# STM32H7x7_CM4 register map
File version: 1.0
CPU: CM4 r0p1, little endian, MPU, FPU, 4 interrupt priority bits
Registers are 32-bit, read-write, reset 0x0 unless marked. A register's access mark holds for its fields unless they carry their own. Offsets are from the block's base; [hi:lo] are bit positions; {n}, {i} and the like mark numbered series; 'fields as' and 'values as' point back to an identical list.

## SAI4 — SAI
Base 0x58005400
Same registers: SAI1 0x40015800, SAI2 0x40015C00, SAI3 0x40016000
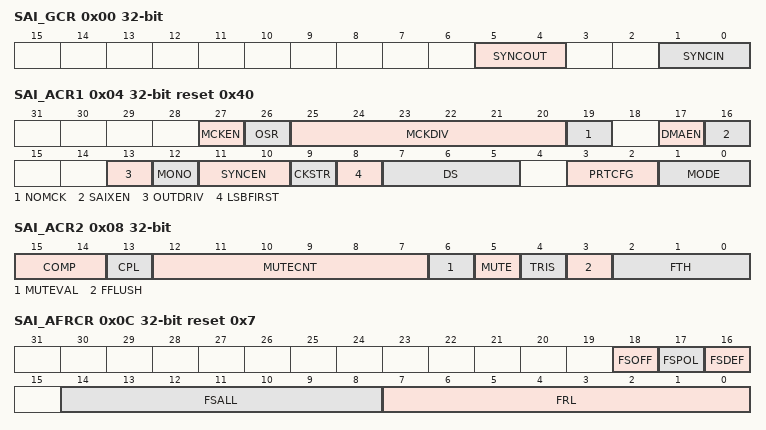
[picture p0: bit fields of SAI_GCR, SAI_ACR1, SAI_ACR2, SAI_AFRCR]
0x00 SAI_GCR — Global configuration register
  [5:4] SYNCOUT — Synchronization outputs These bits are set and cleared by software.
  [1:0] SYNCIN — Synchronization inputs
0x04 SAI_ACR1 reset 0x40 — Configuration register 1
  [27] MCKEN — Master clock generation enable
  [26] OSR — Oversampling ratio for master clock
  [25:20] MCKDIV — Master clock divider. These bits are set and cleared by software. These bits are meaningless when the audio block operates in slave mode. They have to be configured when the audio block is disabled. Others: the master clock frequency is calculated accordingly to the following formula:
  [19] NOMCK — No divider
  [17] DMAEN — DMA enable. This bit is set and cleared by software. Note: Since the audio block defaults to operate as a transmitter after reset, the MODE[1:0] bits must be configured before setting DMAEN to avoid a DMA request in receiver mode.
  [16] SAIXEN — Audio block enable where x is A or B. This bit is set by software. To switch off the audio block, the application software must program this bit to 0 and poll the bit till it reads back 0, meaning that the block is completely disabled. Before setting this bit to 1, check that it is set to 0, otherwise the enable command will not be taken into account. This bit allows to control the state of SAIx audio block. If it is disabled when an audio frame transfer is ongoing, the ongoing transfer completes and the cell is fully disabled at the end of this audio frame transfer. Note: When SAIx block is configured in master mode, the clock must be present on the input of SAIx before setting SAIXEN bit.
  [13] OUTDRIV — Output drive. This bit is set and cleared by software. Note: This bit has to be set before enabling the audio block and after the audio block configuration.
  [12] MONO — Mono mode. This bit is set and cleared by software. It is meaningful only when the number of slots is equal to 2. When the mono mode is selected, slot 0 data are duplicated on slot 1 when the audio block operates as a transmitter. In reception mode, the slot1 is discarded and only the data received from slot 0 are stored. Refer to Section: Mono/stereo mode for more details.
  [11:10] SYNCEN — Synchronization enable. These bits are set and cleared by software. They must be configured when the audio sub-block is disabled. Note: The audio sub-block should be configured as asynchronous when SPDIF mode is enabled.
  [9] CKSTR — Clock strobing edge. This bit is set and cleared by software. It must be configured when the audio block is disabled. This bit has no meaning in SPDIF audio protocol.
  [8] LSBFIRST — Least significant bit first. This bit is set and cleared by software. It must be configured when the audio block is disabled. This bit has no meaning in AC97 audio protocol since AC97 data are always transferred with the MSB first. This bit has no meaning in SPDIF audio protocol since in SPDIF data are always transferred with LSB first.
  [7:5] DS — Data size. These bits are set and cleared by software. These bits are ignored when the SPDIF protocols are selected (bit PRTCFG[1:0]), because the frame and the data size are fixed in such case. When the companding mode is selected through COMP[1:0] bits, DS[1:0] are ignored since the data size is fixed to 8 bits by the algorithm. These bits must be configured when the audio block is disabled.
  [3:2] PRTCFG — Protocol configuration. These bits are set and cleared by software. These bits have to be configured when the audio block is disabled.
  [1:0] MODE — SAIx audio block mode immediately
0x08 SAI_ACR2 access per field — Configuration register 2
  [15:14] COMP rw — Companding mode. These bits are set and cleared by software. The -Law and the A-Law log are a part of the CCITT G.711 recommendation, the type of complement that will be used depends on CPL bit. The data expansion or data compression are determined by the state of bit MODE[0]. The data compression is applied if the audio block is configured as a transmitter. The data expansion is automatically applied when the audio block is configured as a receiver. Refer to Section: Companding mode for more details. Note: Companding mode is applicable only when TDM is selected.
  [13] CPL rw — Complement bit. This bit is set and cleared by software. It defines the type of complement to be used for companding mode Note: This bit has effect only when the companding mode is -Law algorithm or A-Law algorithm.
  [12:7] MUTECNT rw — Mute counter. These bits are set and cleared by software. They are used only in reception mode. The value set in these bits is compared to the number of consecutive mute frames detected in reception. When the number of mute frames is equal to this value, the flag MUTEDET will be set and an interrupt will be generated if bit MUTEDETIE is set. Refer to Section: Mute mode for more details.
  [6] MUTEVAL rw — Mute value. This bit is set and cleared by software.It must be written before enabling the audio block: SAIXEN. This bit is meaningful only when the audio block operates as a transmitter, the number of slots is lower or equal to 2 and the MUTE bit is set. If more slots are declared, the bit value sent during the transmission in mute mode is equal to 0, whatever the value of MUTEVAL. if the number of slot is lower or equal to 2 and MUTEVAL = 1, the MUTE value transmitted for each slot is the one sent during the previous frame. Refer to Section: Mute mode for more details. Note: This bit is meaningless and should not be used for SPDIF audio blocks.
  [5] MUTE rw — Mute. This bit is set and cleared by software. It is meaningful only when the audio block operates as a transmitter. The MUTE value is linked to value of MUTEVAL if the number of slots is lower or equal to 2, or equal to 0 if it is greater than 2. Refer to Section: Mute mode for more details. Note: This bit is meaningless and should not be used for SPDIF audio blocks.
  [4] TRIS rw — Tristate management on data line. This bit is set and cleared by software. It is meaningful only if the audio block is configured as a transmitter. This bit is not used when the audio block is configured in SPDIF mode. It should be configured when SAI is disabled. Refer to Section: Output data line management on an inactive slot for more details.
  [3] FFLUSH wo — FIFO flush. This bit is set by software. It is always read as 0. This bit should be configured when the SAI is disabled.
  [2:0] FTH rw — FIFO threshold. This bit is set and cleared by software.
0x0C SAI_AFRCR access per field reset 0x7 — This register has no meaning in AC97 and SPDIF audio protocol
  [18] FSOFF rw — Frame synchronization offset. This bit is set and cleared by software. It is meaningless and is not used in AC97 or SPDIF audio block configuration. This bit must be configured when the audio block is disabled.
  [17] FSPOL rw — Frame synchronization polarity. This bit is set and cleared by software. It is used to configure the level of the start of frame on the FS signal. It is meaningless and is not used in AC97 or SPDIF audio block configuration. This bit must be configured when the audio block is disabled.
  [16] FSDEF ro — Frame synchronization definition. This bit is set and cleared by software. When the bit is set, the number of slots defined in the SAI_xSLOTR register has to be even. It means that half of this number of slots will be dedicated to the left channel and the other slots for the right channel (e.g: this bit has to be set for I2S or MSB/LSB-justified protocols...). This bit is meaningless and is not used in AC97 or SPDIF audio block configuration. It must be configured when the audio block is disabled.
  [14:8] FSALL rw — Frame synchronization active level length. These bits are set and cleared by software. They specify the length in number of bit clock (SCK) + 1 (FSALL[6:0] + 1) of the active level of the FS signal in the audio frame These bits are meaningless and are not used in AC97 or SPDIF audio block configuration. They must be configured when the audio block is disabled.
  [7:0] FRL rw — Frame length. These bits are set and cleared by software. They define the audio frame length expressed in number of SCK clock cycles: the number of bits in the frame is equal to FRL[7:0] + 1. The minimum number of bits to transfer in an audio frame must be equal to 8, otherwise the audio block will behaves in an unexpected way. This is the case when the data size is 8 bits and only one slot 0 is defined in NBSLOT[4:0] of SAI_xSLOTR register (NBSLOT[3:0] = 0000). In master mode, if the master clock (available on MCLK_x pin) is used, the frame length should be aligned with a number equal to a power of 2, ranging from 8 to 256. When the master clock is not used (NODIV = 1), it is recommended to program the frame length to an value ranging from 8 to 256. These bits are meaningless and are not used in AC97 or SPDIF audio block configuration.
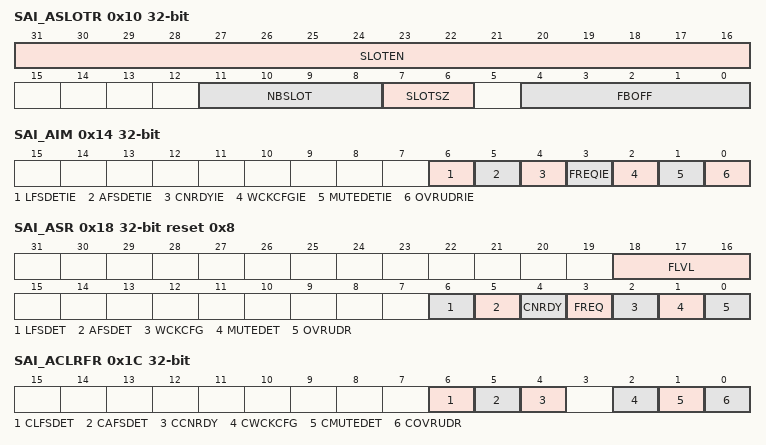
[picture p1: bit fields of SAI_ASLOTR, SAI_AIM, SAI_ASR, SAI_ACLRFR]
0x10 SAI_ASLOTR — This register has no meaning in AC97 and SPDIF audio protocol
  [31:16] SLOTEN — Slot enable. These bits are set and cleared by software. Each SLOTEN bit corresponds to a slot position from 0 to 15 (maximum 16 slots). The slot must be enabled when the audio block is disabled. They are ignored in AC97 or SPDIF mode.
  [11:8] NBSLOT — Number of slots in an audio frame. These bits are set and cleared by software. The value set in this bitfield represents the number of slots + 1 in the audio frame (including the number of inactive slots). The maximum number of slots is 16. The number of slots should be even if FSDEF bit in the SAI_xFRCR register is set. The number of slots must be configured when the audio block is disabled. They are ignored in AC97 or SPDIF mode.
  [7:6] SLOTSZ — Slot size This bits is set and cleared by software. The slot size must be higher or equal to the data size. If this condition is not respected, the behavior of the SAI will be undetermined. Refer to Section: Output data line management on an inactive slot for information on how to drive SD line. These bits must be set when the audio block is disabled. They are ignored in AC97 or SPDIF mode.
  [4:0] FBOFF — First bit offset These bits are set and cleared by software. The value set in this bitfield defines the position of the first data transfer bit in the slot. It represents an offset value. In transmission mode, the bits outside the data field are forced to 0. In reception mode, the extra received bits are discarded. These bits must be set when the audio block is disabled. They are ignored in AC97 or SPDIF mode.
0x14 SAI_AIM — Interrupt mask register 2
  [6] LFSDETIE — Late frame synchronization detection interrupt enable. This bit is set and cleared by software. When this bit is set, an interrupt will be generated if the LFSDET bit is set in the SAI_xSR register. This bit is meaningless in AC97, SPDIF mode or when the audio block operates as a master.
  [5] AFSDETIE — Anticipated frame synchronization detection interrupt enable. This bit is set and cleared by software. When this bit is set, an interrupt will be generated if the AFSDET bit in the SAI_xSR register is set. This bit is meaningless in AC97, SPDIF mode or when the audio block operates as a master.
  [4] CNRDYIE — Codec not ready interrupt enable (AC97). This bit is set and cleared by software. When the interrupt is enabled, the audio block detects in the slot 0 (tag0) of the AC97 frame if the Codec connected to this line is ready or not. If it is not ready, the CNRDY flag in the SAI_xSR register is set and an interruption i generated. This bit has a meaning only if the AC97 mode is selected through PRTCFG[1:0] bits and the audio block is operates as a receiver.
  [3] FREQIE — FIFO request interrupt enable. This bit is set and cleared by software. When this bit is set, an interrupt is generated if the FREQ bit in the SAI_xSR register is set. Since the audio block defaults to operate as a transmitter after reset, the MODE bit must be configured before setting FREQIE to avoid a parasitic interruption in receiver mode,
  [2] WCKCFGIE — Wrong clock configuration interrupt enable. This bit is set and cleared by software. This bit is taken into account only if the audio block is configured as a master (MODE[1] = 0) and NODIV = 0. It generates an interrupt if the WCKCFG flag in the SAI_xSR register is set. Note: This bit is used only in TDM mode and is meaningless in other modes.
  [1] MUTEDETIE — Mute detection interrupt enable. This bit is set and cleared by software. When this bit is set, an interrupt is generated if the MUTEDET bit in the SAI_xSR register is set. This bit has a meaning only if the audio block is configured in receiver mode.
  [0] OVRUDRIE — Overrun/underrun interrupt enable. This bit is set and cleared by software. When this bit is set, an interrupt is generated if the OVRUDR bit in the SAI_xSR register is set.
0x18 SAI_ASR ro reset 0x8 — Status register
  [18:16] FLVL — FIFO level threshold. This bit is read only. The FIFO level threshold flag is managed only by hardware and its setting depends on SAI block configuration (transmitter or receiver mode). If the SAI block is configured as transmitter: If SAI block is configured as receiver:
  [6] LFSDET — Late frame synchronization detection. This bit is read only. This flag can be set only if the audio block is configured in slave mode. It is not used in AC97 or SPDIF mode. It can generate an interrupt if LFSDETIE bit is set in the SAI_xIM register. This flag is cleared when the software sets bit CLFSDET in SAI_xCLRFR register
  [5] AFSDET — Anticipated frame synchronization detection. This bit is read only. This flag can be set only if the audio block is configured in slave mode. It is not used in AC97or SPDIF mode. It can generate an interrupt if AFSDETIE bit is set in SAI_xIM register. This flag is cleared when the software sets CAFSDET bit in SAI_xCLRFR register.
  [4] CNRDY — Codec not ready. This bit is read only. This bit is used only when the AC97 audio protocol is selected in the SAI_xCR1 register and configured in receiver mode. It can generate an interrupt if CNRDYIE bit is set in SAI_xIM register. This flag is cleared when the software sets CCNRDY bit in SAI_xCLRFR register.
  [3] FREQ — FIFO request. This bit is read only. The request depends on the audio block configuration: If the block is configured in transmission mode, the FIFO request is related to a write request operation in the SAI_xDR. If the block configured in reception, the FIFO request related to a read request operation from the SAI_xDR. This flag can generate an interrupt if FREQIE bit is set in SAI_xIM register.
  [2] WCKCFG — Wrong clock configuration flag. This bit is read only. This bit is used only when the audio block operates in master mode (MODE[1] = 0) and NODIV = 0. It can generate an interrupt if WCKCFGIE bit is set in SAI_xIM register. This flag is cleared when the software sets CWCKCFG bit in SAI_xCLRFR register.
  [1] MUTEDET — Mute detection. This bit is read only. This flag is set if consecutive 0 values are received in each slot of a given audio frame and for a consecutive number of audio frames (set in the MUTECNT bit in the SAI_xCR2 register). It can generate an interrupt if MUTEDETIE bit is set in SAI_xIM register. This flag is cleared when the software sets bit CMUTEDET in the SAI_xCLRFR register.
  [0] OVRUDR — Overrun / underrun. This bit is read only. The overrun and underrun conditions can occur only when the audio block is configured as a receiver and a transmitter, respectively. It can generate an interrupt if OVRUDRIE bit is set in SAI_xIM register. This flag is cleared when the software sets COVRUDR bit in SAI_xCLRFR register.
0x1C SAI_ACLRFR wo — Clear flag register
  [6] CLFSDET — Clear late frame synchronization detection flag. This bit is write only. Programming this bit to 1 clears the LFSDET flag in the SAI_xSR register. This bit is not used in AC97or SPDIF mode Reading this bit always returns the value 0.
  [5] CAFSDET — Clear anticipated frame synchronization detection flag. This bit is write only. Programming this bit to 1 clears the AFSDET flag in the SAI_xSR register. It is not used in AC97or SPDIF mode. Reading this bit always returns the value 0.
  [4] CCNRDY — Clear Codec not ready flag. This bit is write only. Programming this bit to 1 clears the CNRDY flag in the SAI_xSR register. This bit is used only when the AC97 audio protocol is selected in the SAI_xCR1 register. Reading this bit always returns the value 0.
  [2] CWCKCFG — Clear wrong clock configuration flag. This bit is write only. Programming this bit to 1 clears the WCKCFG flag in the SAI_xSR register. This bit is used only when the audio block is set as master (MODE[1] = 0) and NODIV = 0 in the SAI_xCR1 register. Reading this bit always returns the value 0.
  [1] CMUTEDET — Mute detection flag. This bit is write only. Programming this bit to 1 clears the MUTEDET flag in the SAI_xSR register. Reading this bit always returns the value 0.
  [0] COVRUDR — Clear overrun / underrun. This bit is write only. Programming this bit to 1 clears the OVRUDR flag in the SAI_xSR register. Reading this bit always returns the value 0.
0x20 SAI_ADR — Data register
  [31:0] DATA — Data A write to this register loads the FIFO provided the FIFO is not full. A read from this register empties the FIFO if the FIFO is not empty.
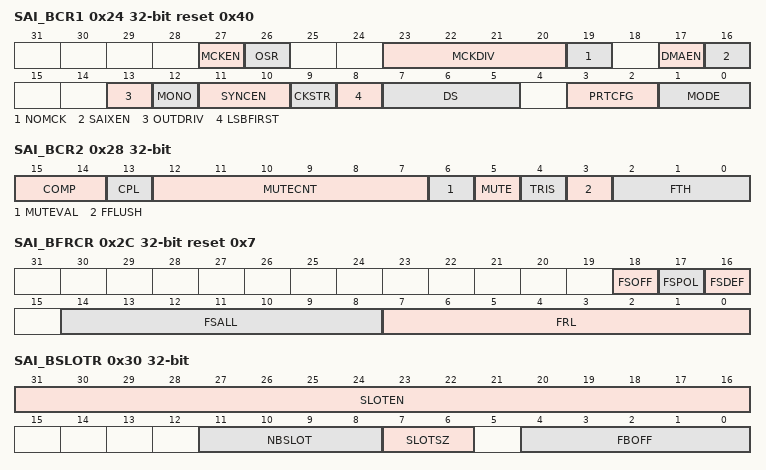
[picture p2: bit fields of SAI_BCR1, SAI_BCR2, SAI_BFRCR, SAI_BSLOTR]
0x24 SAI_BCR1 reset 0x40 — Configuration register 1
  [27] MCKEN — Master clock generation enable
  [26] OSR — Oversampling ratio for master clock
  [23:20] MCKDIV — Master clock divider. These bits are set and cleared by software. These bits are meaningless when the audio block operates in slave mode. They have to be configured when the audio block is disabled. Others: the master clock frequency is calculated accordingly to the following formula:
  [19] NOMCK — No divider
  [17] DMAEN — DMA enable. This bit is set and cleared by software. Note: Since the audio block defaults to operate as a transmitter after reset, the MODE[1:0] bits must be configured before setting DMAEN to avoid a DMA request in receiver mode.
  [16] SAIXEN — Audio block enable where x is A or B. This bit is set by software. To switch off the audio block, the application software must program this bit to 0 and poll the bit till it reads back 0, meaning that the block is completely disabled. Before setting this bit to 1, check that it is set to 0, otherwise the enable command will not be taken into account. This bit allows to control the state of SAIx audio block. If it is disabled when an audio frame transfer is ongoing, the ongoing transfer completes and the cell is fully disabled at the end of this audio frame transfer. Note: When SAIx block is configured in master mode, the clock must be present on the input of SAIx before setting SAIXEN bit.
  [13] OUTDRIV — Output drive. This bit is set and cleared by software. Note: This bit has to be set before enabling the audio block and after the audio block configuration.
  [12] MONO — Mono mode. This bit is set and cleared by software. It is meaningful only when the number of slots is equal to 2. When the mono mode is selected, slot 0 data are duplicated on slot 1 when the audio block operates as a transmitter. In reception mode, the slot1 is discarded and only the data received from slot 0 are stored. Refer to Section: Mono/stereo mode for more details.
  [11:10] SYNCEN — Synchronization enable. These bits are set and cleared by software. They must be configured when the audio sub-block is disabled. Note: The audio sub-block should be configured as asynchronous when SPDIF mode is enabled.
  [9] CKSTR — Clock strobing edge. This bit is set and cleared by software. It must be configured when the audio block is disabled. This bit has no meaning in SPDIF audio protocol.
  [8] LSBFIRST — Least significant bit first. This bit is set and cleared by software. It must be configured when the audio block is disabled. This bit has no meaning in AC97 audio protocol since AC97 data are always transferred with the MSB first. This bit has no meaning in SPDIF audio protocol since in SPDIF data are always transferred with LSB first.
  [7:5] DS — Data size. These bits are set and cleared by software. These bits are ignored when the SPDIF protocols are selected (bit PRTCFG[1:0]), because the frame and the data size are fixed in such case. When the companding mode is selected through COMP[1:0] bits, DS[1:0] are ignored since the data size is fixed to 8 bits by the algorithm. These bits must be configured when the audio block is disabled.
  [3:2] PRTCFG — Protocol configuration. These bits are set and cleared by software. These bits have to be configured when the audio block is disabled.
  [1:0] MODE — SAIx audio block mode immediately
0x28 SAI_BCR2 access per field — Configuration register 2
  fields as SAI_ACR2
0x2C SAI_BFRCR access per field reset 0x7 — This register has no meaning in AC97 and SPDIF audio protocol
  fields as SAI_AFRCR
0x30 SAI_BSLOTR — This register has no meaning in AC97 and SPDIF audio protocol
  fields as SAI_ASLOTR
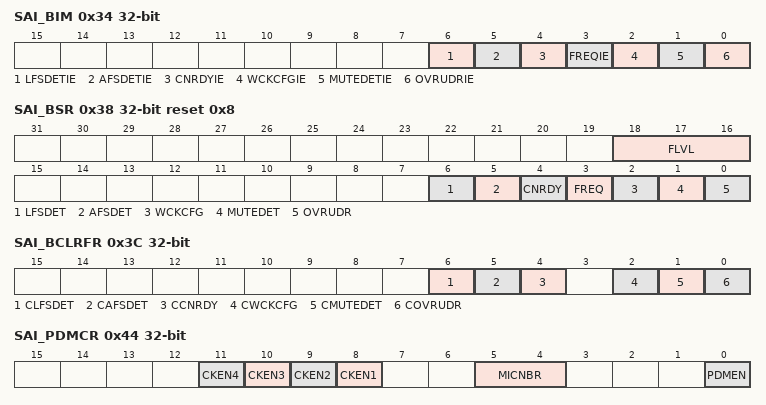
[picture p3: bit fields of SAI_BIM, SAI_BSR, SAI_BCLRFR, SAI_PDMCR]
0x34 SAI_BIM — Interrupt mask register 2
  fields as SAI_AIM
0x38 SAI_BSR ro reset 0x8 — Status register
  fields as SAI_ASR
0x3C SAI_BCLRFR wo — Clear flag register
  fields as SAI_ACLRFR
0x40 SAI_BDR — Data register
  fields as SAI_ADR
0x44 SAI_PDMCR — PDM control register
  [n+7] CKEN{n} (n=1..4) — Clock enable of bitstream clock number {n}
  [5:4] MICNBR — Number of microphones
  [0] PDMEN — PDM enable
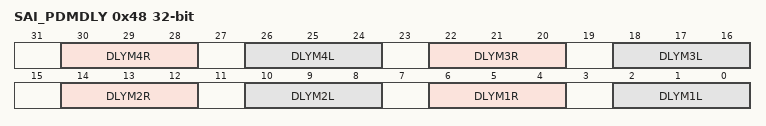
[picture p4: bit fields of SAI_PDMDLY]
0x48 SAI_PDMDLY — PDM delay register
  [30:28] DLYM4R — Delay line for second microphone of pair 4
  [26:24] DLYM4L — Delay line for first microphone of pair 4
  [22:20] DLYM3R — Delay line for second microphone of pair 3
  [18:16] DLYM3L — Delay line for first microphone of pair 3
  [14:12] DLYM2R — Delay line for second microphone of pair 2
  [10:8] DLYM2L — Delay line for first microphone of pair 2
  [6:4] DLYM1R — Delay line adjust for second microphone of pair 1
  [2:0] DLYM1L — Delay line adjust for first microphone of pair 1
